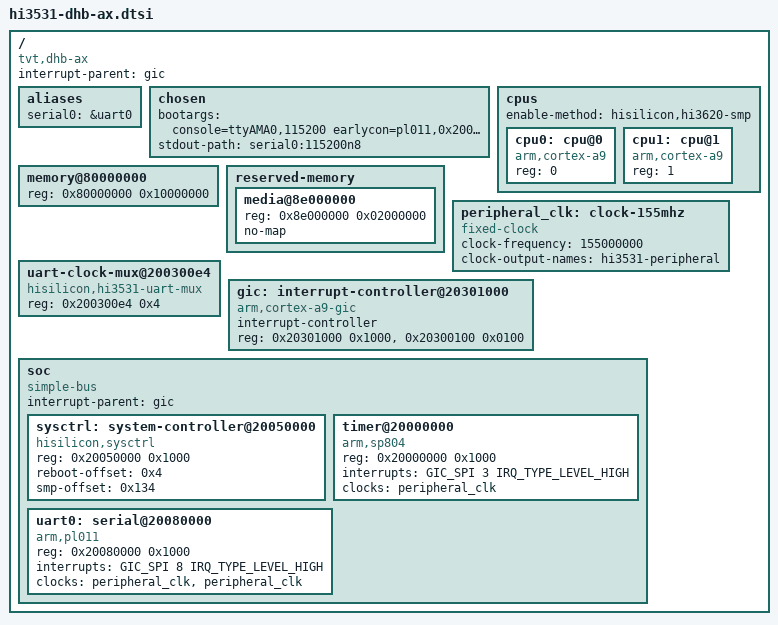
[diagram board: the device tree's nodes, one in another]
// SPDX-License-Identifier: GPL-2.0-only
/*
 * Shared base for the Shenzhen TVT DVR marked DHB_AX V1.2 on the PCB
 * (HiSilicon Hi3531 "godnet").
 *
 * Only hardware confirmed against the running DVR's /proc/iomem,
 * /proc/interrupts and early boot log is described here.
 */

#include <dt-bindings/interrupt-controller/arm-gic.h>

/ {
	compatible = "tvt,dhb-ax", "hisilicon,hi3531";

	#address-cells = <1>;
	#size-cells = <1>;
	interrupt-parent = <&gic>;

	aliases {
		serial0 = &uart0;
	};

	chosen {
		bootargs = "console=ttyAMA0,115200 earlycon=pl011,0x20080000 keep_bootcon ignore_loglevel rdinit=/init";
		stdout-path = "serial0:115200n8";
	};

	/*
	 * Both cores.  The vendor releases CPU1 by writing the physical
	 * address of the secondary entry point to SYS_CTRL + 0x134 and then
	 * sending a soft interrupt, which the boot monitor is waiting for.
	 * That is exactly what mainline's "hisilicon,hi3620-smp" method does,
	 * so no new code is needed: it enables the Cortex-A9 SCU, finds the
	 * sysctrl node below, and uses its smp-offset.  The CPU power-control
	 * step in that method no-ops here because this board has no
	 * "hisilicon,hi3620-cpu-ctrl" node.
	 */
	cpus {
		#address-cells = <1>;
		#size-cells = <0>;
		enable-method = "hisilicon,hi3620-smp";

		cpu0: cpu@0 {
			compatible = "arm,cortex-a9";
			device_type = "cpu";
			reg = <0>;
		};

		cpu1: cpu@1 {
			compatible = "arm,cortex-a9";
			device_type = "cpu";
			reg = <1>;
		};
	};

	memory@80000000 {
		device_type = "memory";
		reg = <0x80000000 0x10000000>;
	};

	reserved-memory {
		#address-cells = <1>;
		#size-cells = <1>;
		ranges;

		/* Keep the stock firmware's upper 32 MiB media carveout reserved. */
		media@8e000000 {
			reg = <0x8e000000 0x02000000>;
			no-map;
		};
	};

	peripheral_clk: clock-155mhz {
		compatible = "fixed-clock";
		#clock-cells = <0>;
		clock-frequency = <155000000>;
		clock-output-names = "hi3531-peripheral";
	};

	uart-clock-mux@200300e4 {
		compatible = "hisilicon,hi3531-uart-mux";
		reg = <0x200300e4 0x4>;
	};

	gic: interrupt-controller@20301000 {
		compatible = "arm,cortex-a9-gic";
		#interrupt-cells = <3>;
		#address-cells = <0>;
		interrupt-controller;
		reg = <0x20301000 0x1000>,
		      <0x20300100 0x0100>;
	};

	soc: soc {
		compatible = "simple-bus";
		#address-cells = <1>;
		#size-cells = <1>;
		interrupt-parent = <&gic>;
		ranges;

		/*
		 * Restart method.  The vendor 3.0.8 arch_reset() writes to
		 * SYS_CTRL_BASE + REG_SC_SYSRES, which its platform.h defines
		 * as 0x20050000 + 0x4.  That is the same shape as the stock
		 * "hisilicon,sysctrl" reboot support, so no driver change is
		 * needed.
		 */
		sysctrl: system-controller@20050000 {
			compatible = "hisilicon,sysctrl";
			reg = <0x20050000 0x1000>;
			reboot-offset = <0x4>;
			/* Where CPU1's entry point is written; SMP_COREX_START_ADDR_REG
			 * in the vendor platsmp.h. */
			smp-offset = <0x134>;
		};

		timer@20000000 {
			compatible = "arm,sp804", "arm,primecell";
			reg = <0x20000000 0x1000>;
			interrupts = <GIC_SPI 3 IRQ_TYPE_LEVEL_HIGH>;
			clocks = <&peripheral_clk>;
			clock-names = "apb_pclk";
		};

		uart0: serial@20080000 {
			compatible = "arm,pl011", "arm,primecell";
			reg = <0x20080000 0x1000>;
			interrupts = <GIC_SPI 8 IRQ_TYPE_LEVEL_HIGH>;
			clocks = <&peripheral_clk>, <&peripheral_clk>;
			clock-names = "uartclk", "apb_pclk";
		};
	};
};
